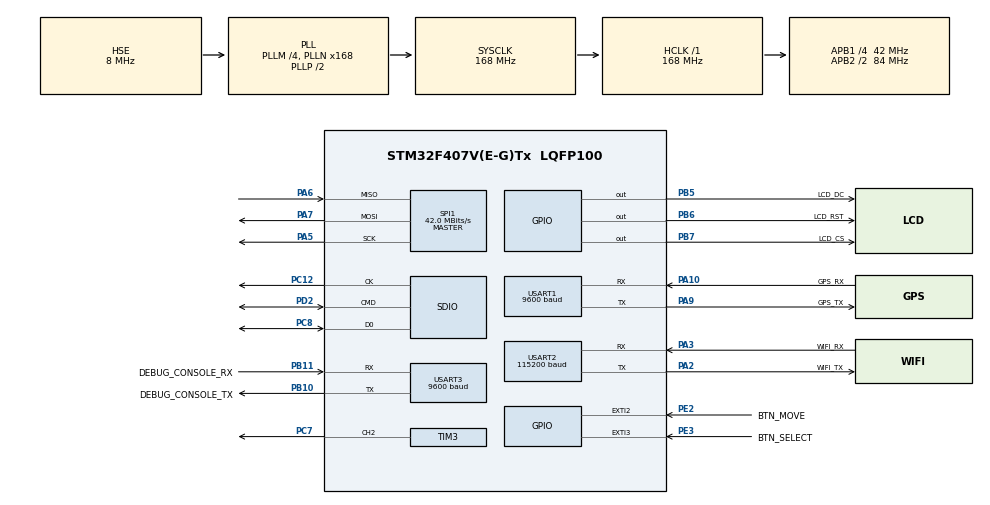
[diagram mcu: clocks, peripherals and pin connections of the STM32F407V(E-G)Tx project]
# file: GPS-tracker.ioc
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Dma.Request0=USART2_RX
Dma.Request1=USART1_RX
Dma.USART1_RX.1.Direction=DMA_PERIPH_TO_MEMORY
Dma.USART1_RX.1.FIFOMode=DMA_FIFOMODE_DISABLE
Dma.USART1_RX.1.Instance=DMA2_Stream5
Dma.USART1_RX.1.MemDataAlignment=DMA_MDATAALIGN_BYTE
Dma.USART1_RX.1.MemInc=DMA_MINC_ENABLE
Dma.USART1_RX.1.Mode=DMA_CIRCULAR
Dma.USART1_RX.1.PeriphDataAlignment=DMA_PDATAALIGN_BYTE
Dma.USART1_RX.1.PeriphInc=DMA_PINC_DISABLE
Dma.USART1_RX.1.Priority=DMA_PRIORITY_LOW
Dma.USART2_RX.0.Direction=DMA_PERIPH_TO_MEMORY
Dma.USART2_RX.0.FIFOMode=DMA_FIFOMODE_DISABLE
Dma.USART2_RX.0.Instance=DMA1_Stream5
Dma.USART2_RX.0.MemDataAlignment=DMA_MDATAALIGN_BYTE
Dma.USART2_RX.0.MemInc=DMA_MINC_ENABLE
Dma.USART2_RX.0.Mode=DMA_CIRCULAR
Dma.USART2_RX.0.PeriphDataAlignment=DMA_PDATAALIGN_BYTE
Dma.USART2_RX.0.PeriphInc=DMA_PINC_DISABLE
Dma.USART2_RX.0.Priority=DMA_PRIORITY_LOW
FATFS._FS_LOCK=3
FATFS._MAX_LFN=50
FATFS._MAX_SS=4096
FATFS._USE_LFN=1
Mcu.Family=STM32F4
Mcu.Name=STM32F407V(E-G)Tx
Mcu.Package=LQFP100
NVIC.DMA1_Stream5_IRQn=true\:0\:0\:true\:false\:true\:false\:true\:true
NVIC.DMA2_Stream5_IRQn=true\:5\:0\:true\:false\:true\:false\:true\:true
NVIC.EXTI2_IRQn=true\:0\:0\:false\:false\:true\:true\:true\:true
NVIC.EXTI3_IRQn=true\:0\:0\:false\:false\:true\:true\:true\:true
NVIC.PriorityGroup=NVIC_PRIORITYGROUP_4
NVIC.SDIO_IRQn=true\:1\:0\:true\:false\:true\:true\:true\:true
NVIC.USART1_IRQn=true\:5\:0\:true\:false\:true\:true\:true\:true
NVIC.USART2_IRQn=true\:0\:0\:true\:false\:true\:true\:true\:true
PA10.GPIO_Label=GPS_RX
PA10.Mode=Asynchronous
PA10.Signal=USART1_RX
PA13.Mode=Serial_Wire
PA13.Signal=SYS_JTMS-SWDIO
PA14.Mode=Serial_Wire
PA14.Signal=SYS_JTCK-SWCLK
PA2.GPIO_Label=WIFI_TX
PA2.Mode=Asynchronous
PA2.Signal=USART2_TX
PA3.GPIO_Label=WIFI_RX
PA3.Mode=Asynchronous
PA3.Signal=USART2_RX
PA5.GPIO_Speed=GPIO_SPEED_FREQ_VERY_HIGH
PA5.Mode=Full_Duplex_Master
PA5.Signal=SPI1_SCK
PA6.GPIO_Mode=GPIO_MODE_AF_PP
PA6.GPIO_PuPd=GPIO_NOPULL
PA6.GPIO_Speed=GPIO_SPEED_FREQ_VERY_HIGH
PA6.Mode=Full_Duplex_Master
PA6.Signal=SPI1_MISO
PA7.GPIO_Speed=GPIO_SPEED_FREQ_VERY_HIGH
PA7.Mode=Full_Duplex_Master
PA7.Signal=SPI1_MOSI
PA9.GPIO_Label=GPS_TX
PA9.Mode=Asynchronous
PA9.Signal=USART1_TX
PB10.GPIO_Label=DEBUG_CONSOLE_TX
PB10.Mode=Asynchronous
PB10.Signal=USART3_TX
PB11.GPIO_Label=DEBUG_CONSOLE_RX
PB11.Mode=Asynchronous
PB11.Signal=USART3_RX
PB5.GPIO_Label=LCD_DC
PB5.GPIO_Speed=GPIO_SPEED_FREQ_LOW
PB5.PinState=GPIO_PIN_SET
PB5.Signal=GPIO_Output
PB6.GPIO_Label=LCD_RST
PB6.GPIO_Speed=GPIO_SPEED_FREQ_LOW
PB6.PinState=GPIO_PIN_SET
PB6.Signal=GPIO_Output
PB7.GPIO_Label=LCD_CS
PB7.GPIO_Speed=GPIO_SPEED_FREQ_LOW
PB7.PinState=GPIO_PIN_SET
PB7.Signal=GPIO_Output
PC12.Mode=SD_1_bit
PC12.Signal=SDIO_CK
PC7.Signal=S_TIM3_CH2
PC8.Mode=SD_1_bit
PC8.Signal=SDIO_D0
PD2.Mode=SD_1_bit
PD2.Signal=SDIO_CMD
PE2.GPIO_Label=BTN_MOVE
PE2.GPIO_ModeDefaultEXTI=GPIO_MODE_IT_RISING_FALLING
PE2.GPIO_PuPd=GPIO_PULLDOWN
PE2.Signal=GPXTI2
PE3.GPIO_Label=BTN_SELECT
PE3.GPIO_ModeDefaultEXTI=GPIO_MODE_IT_RISING_FALLING
PE3.GPIO_PuPd=GPIO_PULLDOWN
PE3.Signal=GPXTI3
PH0-OSC_IN.Mode=HSE-External-Oscillator
PH0-OSC_IN.Signal=RCC_OSC_IN
PH1-OSC_OUT.Mode=HSE-External-Oscillator
PH1-OSC_OUT.Signal=RCC_OSC_OUT
ProjectManager.HeapSize=0x800
ProjectManager.StackSize=0x1200
ProjectManager.TargetToolchain=STM32CubeIDE
RCC.48MHZClocksFreq_Value=48000000
RCC.AHBFreq_Value=168000000
RCC.APB1CLKDivider=RCC_HCLK_DIV4
RCC.APB1Freq_Value=42000000
RCC.APB1TimFreq_Value=84000000
RCC.APB2CLKDivider=RCC_HCLK_DIV2
RCC.APB2Freq_Value=84000000
RCC.APB2TimFreq_Value=168000000
RCC.CortexFreq_Value=168000000
RCC.HCLKFreq_Value=168000000
RCC.HSE_VALUE=8000000
RCC.HSI_VALUE=16000000
RCC.LSE_VALUE=32768
RCC.PLLM=4
RCC.PLLN=168
RCC.PLLQ=7
RCC.PLLSourceVirtual=RCC_PLLSOURCE_HSE
RCC.SYSCLKFreq_VALUE=168000000
RCC.SYSCLKSource=RCC_SYSCLKSOURCE_PLLCLK
RCC.VCOOutputFreq_Value=336000000
SH.S_TIM3_CH2.0=TIM3_CH2,PWM Generation2 CH2
SPI1.BaudRatePrescaler=SPI_BAUDRATEPRESCALER_2
SPI1.CalculateBaudRate=42.0 MBits/s
SPI1.DataSize=SPI_DATASIZE_8BIT
SPI1.Direction=SPI_DIRECTION_2LINES
SPI1.Mode=SPI_MODE_MASTER
SPI1.VirtualType=VM_MASTER
TIM3.Channel-PWM\ Generation2\ CH2=TIM_CHANNEL_2
TIM3.Period=1000-1
TIM3.Prescaler=84-1
USART1.BaudRate=9600
USART1.VirtualMode=VM_ASYNC
USART2.BaudRate=115200
USART2.VirtualMode=VM_ASYNC
USART3.BaudRate=9600
USART3.VirtualMode=VM_ASYNC
VP_FATFS_VS_SDIO.Mode=SDIO
board=custom

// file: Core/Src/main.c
/* USER CODE BEGIN Header */
/**
  ******************************************************************************
  * @file           : main.c
  * @brief          : Main program body
  ******************************************************************************
  * @attention
  *
  * Copyright (c) 2024 STMicroelectronics.
  * All rights reserved.
  *
  * This software is licensed under terms that can be found in the LICENSE file
  * in the root directory of this software component.
  * If no LICENSE file comes with this software, it is provided AS-IS.
  *
  ******************************************************************************
  */
/* USER CODE END Header */
#include "main.h"
#include "fatfs.h"

/* USER CODE BEGIN Includes */
#include "App/app.h"
//#include "LcdDriver/LCD_2inch.h"
//#include "LcdDriver/DEV_Config.h"
//#include "LcdDriver/GUI_Paint.h"
//#include "LcdDriver/fonts.h"
/* USER CODE END Includes */

SD_HandleTypeDef hsd;

SPI_HandleTypeDef hspi1;

TIM_HandleTypeDef htim3;

UART_HandleTypeDef huart1;
UART_HandleTypeDef huart2;
UART_HandleTypeDef huart3;
DMA_HandleTypeDef hdma_usart1_rx;
DMA_HandleTypeDef hdma_usart2_rx;

void SystemClock_Config(void);
static void MX_GPIO_Init(void);
static void MX_DMA_Init(void);
static void MX_USART1_UART_Init(void);
static void MX_SPI1_Init(void);
static void MX_TIM3_Init(void);
static void MX_SDIO_SD_Init(void);
static void MX_USART2_UART_Init(void);
static void MX_USART3_UART_Init(void);

int main(void)
{

  /* MCU Configuration--------------------------------------------------------*/

  /* Reset of all peripherals, Initializes the Flash interface and the Systick. */
  HAL_Init();

  /* Configure the system clock */
  SystemClock_Config();

  /* Initialize all configured peripherals */
  MX_GPIO_Init();
  MX_DMA_Init();
  MX_USART1_UART_Init();
  MX_SPI1_Init();
  MX_TIM3_Init();
  MX_SDIO_SD_Init();
  MX_FATFS_Init();
  MX_USART2_UART_Init();
  MX_USART3_UART_Init();

  /* Infinite loop */
  /* USER CODE BEGIN WHILE */

  applicationMain(&huart1, &huart2, &huart3);

  while (1)
  {
    /* USER CODE END WHILE */

    /* USER CODE BEGIN 3 */

//	  HAL_UART_Transmit(&huart3, "DDD1\r\n", 6, 100);
//	  HAL_Delay(1000);

//	  char testBuffer[255];
//	  memset(testBuffer, 0, 255);
//	  HAL_UART_Receive(&huart2, (uint8_t *) testBuffer, 254, 10000);
//	  testBuffer[254] = '\0';
  }
  /* USER CODE END 3 */
}

void SystemClock_Config(void)
{
  RCC_OscInitTypeDef RCC_OscInitStruct = {0};
  RCC_ClkInitTypeDef RCC_ClkInitStruct = {0};

  /** Configure the main internal regulator output voltage
  */
  __HAL_RCC_PWR_CLK_ENABLE();
  __HAL_PWR_VOLTAGESCALING_CONFIG(PWR_REGULATOR_VOLTAGE_SCALE1);

  /** Initializes the RCC Oscillators according to the specified parameters
  * in the RCC_OscInitTypeDef structure.
  */
  RCC_OscInitStruct.OscillatorType = RCC_OSCILLATORTYPE_HSE;
  RCC_OscInitStruct.HSEState = RCC_HSE_ON;
  RCC_OscInitStruct.PLL.PLLState = RCC_PLL_ON;
  RCC_OscInitStruct.PLL.PLLSource = RCC_PLLSOURCE_HSE;
  RCC_OscInitStruct.PLL.PLLM = 4;
  RCC_OscInitStruct.PLL.PLLN = 168;
  RCC_OscInitStruct.PLL.PLLP = RCC_PLLP_DIV2;
  RCC_OscInitStruct.PLL.PLLQ = 7;
  if (HAL_RCC_OscConfig(&RCC_OscInitStruct) != HAL_OK)
  {
    Error_Handler();
  }

  /** Initializes the CPU, AHB and APB buses clocks
  */
  RCC_ClkInitStruct.ClockType = RCC_CLOCKTYPE_HCLK|RCC_CLOCKTYPE_SYSCLK
                              |RCC_CLOCKTYPE_PCLK1|RCC_CLOCKTYPE_PCLK2;
  RCC_ClkInitStruct.SYSCLKSource = RCC_SYSCLKSOURCE_PLLCLK;
  RCC_ClkInitStruct.AHBCLKDivider = RCC_SYSCLK_DIV1;
  RCC_ClkInitStruct.APB1CLKDivider = RCC_HCLK_DIV4;
  RCC_ClkInitStruct.APB2CLKDivider = RCC_HCLK_DIV2;

  if (HAL_RCC_ClockConfig(&RCC_ClkInitStruct, FLASH_LATENCY_5) != HAL_OK)
  {
    Error_Handler();
  }
}

static void MX_SDIO_SD_Init(void)
{

  hsd.Instance = SDIO;
  hsd.Init.ClockEdge = SDIO_CLOCK_EDGE_RISING;
  hsd.Init.ClockBypass = SDIO_CLOCK_BYPASS_DISABLE;
  hsd.Init.ClockPowerSave = SDIO_CLOCK_POWER_SAVE_DISABLE;
  hsd.Init.BusWide = SDIO_BUS_WIDE_1B;
  hsd.Init.HardwareFlowControl = SDIO_HARDWARE_FLOW_CONTROL_DISABLE;
  hsd.Init.ClockDiv = 0;

}

static void MX_SPI1_Init(void)
{

  /* SPI1 parameter configuration*/
  hspi1.Instance = SPI1;
  hspi1.Init.Mode = SPI_MODE_MASTER;
  hspi1.Init.Direction = SPI_DIRECTION_2LINES;
  hspi1.Init.DataSize = SPI_DATASIZE_8BIT;
  hspi1.Init.CLKPolarity = SPI_POLARITY_LOW;
  hspi1.Init.CLKPhase = SPI_PHASE_1EDGE;
  hspi1.Init.NSS = SPI_NSS_SOFT;
  hspi1.Init.BaudRatePrescaler = SPI_BAUDRATEPRESCALER_2;
  hspi1.Init.FirstBit = SPI_FIRSTBIT_MSB;
  hspi1.Init.TIMode = SPI_TIMODE_DISABLE;
  hspi1.Init.CRCCalculation = SPI_CRCCALCULATION_DISABLE;
  hspi1.Init.CRCPolynomial = 10;
  if (HAL_SPI_Init(&hspi1) != HAL_OK)
  {
    Error_Handler();
  }

}

static void MX_TIM3_Init(void)
{

  TIM_MasterConfigTypeDef sMasterConfig = {0};
  TIM_OC_InitTypeDef sConfigOC = {0};

  htim3.Instance = TIM3;
  htim3.Init.Prescaler = 84-1;
  htim3.Init.CounterMode = TIM_COUNTERMODE_UP;
  htim3.Init.Period = 1000-1;
  htim3.Init.ClockDivision = TIM_CLOCKDIVISION_DIV1;
  htim3.Init.AutoReloadPreload = TIM_AUTORELOAD_PRELOAD_DISABLE;
  if (HAL_TIM_PWM_Init(&htim3) != HAL_OK)
  {
    Error_Handler();
  }
  sMasterConfig.MasterOutputTrigger = TIM_TRGO_RESET;
  sMasterConfig.MasterSlaveMode = TIM_MASTERSLAVEMODE_DISABLE;
  if (HAL_TIMEx_MasterConfigSynchronization(&htim3, &sMasterConfig) != HAL_OK)
  {
    Error_Handler();
  }
  sConfigOC.OCMode = TIM_OCMODE_PWM1;
  sConfigOC.Pulse = 0;
  sConfigOC.OCPolarity = TIM_OCPOLARITY_HIGH;
  sConfigOC.OCFastMode = TIM_OCFAST_DISABLE;
  if (HAL_TIM_PWM_ConfigChannel(&htim3, &sConfigOC, TIM_CHANNEL_2) != HAL_OK)
  {
    Error_Handler();
  }
  HAL_TIM_MspPostInit(&htim3);

}

static void MX_USART1_UART_Init(void)
{

  huart1.Instance = USART1;
  huart1.Init.BaudRate = 9600;
  huart1.Init.WordLength = UART_WORDLENGTH_8B;
  huart1.Init.StopBits = UART_STOPBITS_1;
  huart1.Init.Parity = UART_PARITY_NONE;
  huart1.Init.Mode = UART_MODE_TX_RX;
  huart1.Init.HwFlowCtl = UART_HWCONTROL_NONE;
  huart1.Init.OverSampling = UART_OVERSAMPLING_16;
  if (HAL_UART_Init(&huart1) != HAL_OK)
  {
    Error_Handler();
  }

}

static void MX_USART2_UART_Init(void)
{

  huart2.Instance = USART2;
  huart2.Init.BaudRate = 115200;
  huart2.Init.WordLength = UART_WORDLENGTH_8B;
  huart2.Init.StopBits = UART_STOPBITS_1;
  huart2.Init.Parity = UART_PARITY_NONE;
  huart2.Init.Mode = UART_MODE_TX_RX;
  huart2.Init.HwFlowCtl = UART_HWCONTROL_NONE;
  huart2.Init.OverSampling = UART_OVERSAMPLING_16;
  if (HAL_UART_Init(&huart2) != HAL_OK)
  {
    Error_Handler();
  }

}

static void MX_USART3_UART_Init(void)
{

  huart3.Instance = USART3;
  huart3.Init.BaudRate = 9600;
  huart3.Init.WordLength = UART_WORDLENGTH_8B;
  huart3.Init.StopBits = UART_STOPBITS_1;
  huart3.Init.Parity = UART_PARITY_NONE;
  huart3.Init.Mode = UART_MODE_TX_RX;
  huart3.Init.HwFlowCtl = UART_HWCONTROL_NONE;
  huart3.Init.OverSampling = UART_OVERSAMPLING_16;
  if (HAL_UART_Init(&huart3) != HAL_OK)
  {
    Error_Handler();
  }

}

static void MX_DMA_Init(void)
{

  /* DMA controller clock enable */
  __HAL_RCC_DMA1_CLK_ENABLE();
  __HAL_RCC_DMA2_CLK_ENABLE();

  /* DMA interrupt init */
  /* DMA1_Stream5_IRQn interrupt configuration */
  HAL_NVIC_SetPriority(DMA1_Stream5_IRQn, 0, 0);
  HAL_NVIC_EnableIRQ(DMA1_Stream5_IRQn);
  /* DMA2_Stream5_IRQn interrupt configuration */
  HAL_NVIC_SetPriority(DMA2_Stream5_IRQn, 5, 0);
  HAL_NVIC_EnableIRQ(DMA2_Stream5_IRQn);

}

static void MX_GPIO_Init(void)
{
  GPIO_InitTypeDef GPIO_InitStruct = {0};

  /* GPIO Ports Clock Enable */
  __HAL_RCC_GPIOE_CLK_ENABLE();
  __HAL_RCC_GPIOH_CLK_ENABLE();
  __HAL_RCC_GPIOA_CLK_ENABLE();
  __HAL_RCC_GPIOB_CLK_ENABLE();
  __HAL_RCC_GPIOC_CLK_ENABLE();
  __HAL_RCC_GPIOD_CLK_ENABLE();

  /*Configure GPIO pin Output Level */
  HAL_GPIO_WritePin(GPIOB, LCD_DC_Pin|LCD_RST_Pin|LCD_CS_Pin, GPIO_PIN_SET);

  /*Configure GPIO pins : BTN_MOVE_Pin BTN_SELECT_Pin */
  GPIO_InitStruct.Pin = BTN_MOVE_Pin|BTN_SELECT_Pin;
  GPIO_InitStruct.Mode = GPIO_MODE_IT_RISING_FALLING;
  GPIO_InitStruct.Pull = GPIO_PULLDOWN;
  HAL_GPIO_Init(GPIOE, &GPIO_InitStruct);

  /*Configure GPIO pins : LCD_DC_Pin LCD_RST_Pin LCD_CS_Pin */
  GPIO_InitStruct.Pin = LCD_DC_Pin|LCD_RST_Pin|LCD_CS_Pin;
  GPIO_InitStruct.Mode = GPIO_MODE_OUTPUT_PP;
  GPIO_InitStruct.Pull = GPIO_NOPULL;
  GPIO_InitStruct.Speed = GPIO_SPEED_FREQ_LOW;
  HAL_GPIO_Init(GPIOB, &GPIO_InitStruct);

  /* EXTI interrupt init*/
  HAL_NVIC_SetPriority(EXTI2_IRQn, 0, 0);
  HAL_NVIC_EnableIRQ(EXTI2_IRQn);

  HAL_NVIC_SetPriority(EXTI3_IRQn, 0, 0);
  HAL_NVIC_EnableIRQ(EXTI3_IRQn);

}

void Error_Handler(void)
{
  __disable_irq();
  while (1)
  {
  }
}
